# PIC32MK0512GPK100 register map
Vendor: Microchip
Registers are 32-bit, read-write, reset 0x0 unless marked. A register's access mark holds for its fields unless they carry their own. Addresses are absolute, and some are shared; only a register's first bit layout is shown; [hi:lo] are bit positions; {n}, {i} and the like mark numbered series; 'fields as' and 'values as' point back to an identical list.

## RTCC
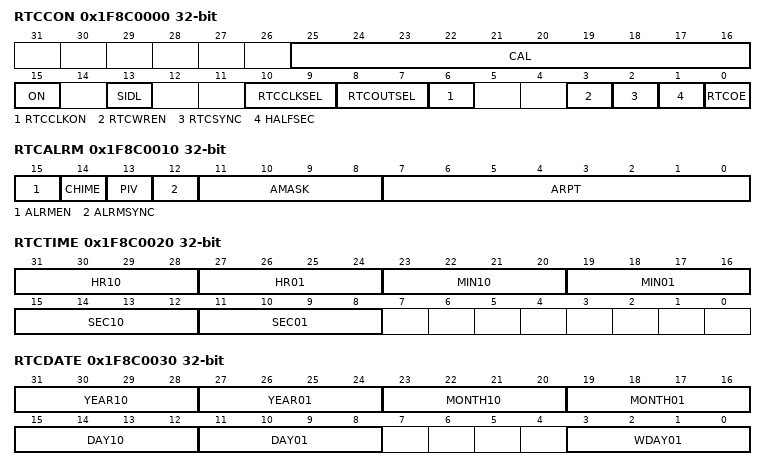
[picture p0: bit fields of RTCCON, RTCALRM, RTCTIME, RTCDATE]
0x1F8C0000 RTCCON
  [25:16] CAL, [15] ON, [13] SIDL, [10:9] RTCCLKSEL, [8:7] RTCOUTSEL, [6] RTCCLKON, [3] RTCWREN, [2] RTCSYNC ro, [1] HALFSEC ro, [0] RTCOE
0x1F8C0010 RTCALRM
  [15] ALRMEN, [14] CHIME, [13] PIV, [12] ALRMSYNC, [11:8] AMASK, [7:0] ARPT
0x1F8C0020 RTCTIME reset not defined — (power-on value 000xxxxxxxxxxxxx0xxxxxxx--------)
  [31:28] HR10, [27:24] HR01, [23:20] MIN10, [19:16] MIN01, [15:12] SEC10, [11:8] SEC01
0x1F8C0030 RTCDATE reset not defined — (power-on value xxxxxxxx000xxxxx00xxxxxx----0xxx)
  [31:28] YEAR10, [27:24] YEAR01, [23:20] MONTH10, [19:16] MONTH01, [15:12] DAY10, [11:8] DAY01, [3:0] WDAY01
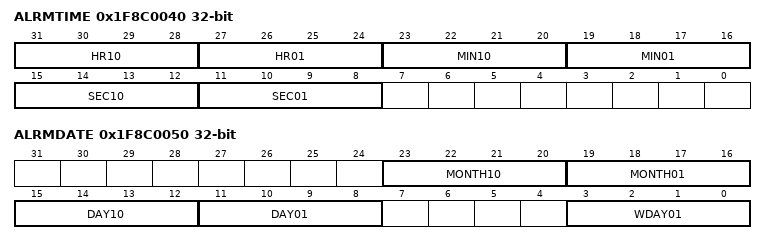
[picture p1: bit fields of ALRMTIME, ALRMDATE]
0x1F8C0040 ALRMTIME reset not defined — (power-on value 000xxxxx0xxxxxxx0xxxxxxx--------)
  fields as RTCTIME
0x1F8C0050 ALRMDATE reset not defined — (power-on value --------000xxxxx00xxxxxx----0xxx)
  [23:20] MONTH10, [19:16] MONTH01, [15:12] DAY10, [11:8] DAY01, [3:0] WDAY01

## lpwr_deep_sleep_ctrl
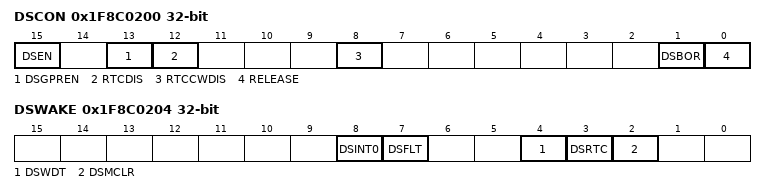
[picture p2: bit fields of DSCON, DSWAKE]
0x1F8C0200 DSCON
  [15] DSEN, [13] DSGPREN, [12] RTCDIS, [8] RTCCWDIS, [1] DSBOR, [0] RELEASE
0x1F8C0204 DSWAKE
  [8] DSINT0, [7] DSFLT, [4] DSWDT, [3] DSRTC, [2] DSMCLR
0x1F8C0208 DSGPR0
  [31:0] DSGPR
{0x1F8C020C+4i} DSGPR{i} (i=1..32)
  [31:0] DSGPR

## SB
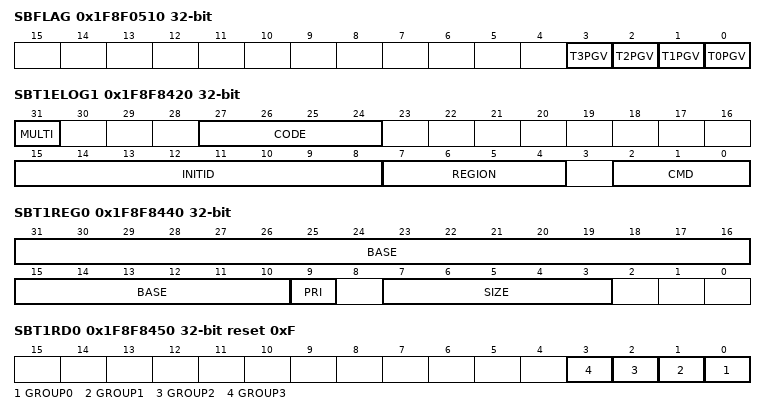
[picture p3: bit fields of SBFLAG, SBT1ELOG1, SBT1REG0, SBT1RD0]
0x1F8F0510 SBFLAG ro
  [n] T{n}PGV (n=0..3)
0x1F8F8420 SBT1ELOG1
  [31] MULTI, [27:24] CODE, [15:8] INITID ro, [7:4] REGION ro, [2:0] CMD ro
0x1F8F8424 SBT1ELOG2 ro
  [1:0] GROUP
0x1F8F8428 SBT1ECON
  [24] ERRP
0x1F8F8430 SBT1ECLRS ro
  [0] CLEAR
0x1F8F8438 SBT1ECLRM ro
  [0] CLEAR
0x1F8F8440 SBT1REG0 reset not defined — (power-on value 0000000000000000000000x-00000---)
  [31:10] BASE, [9] PRI ro, [7:3] SIZE
0x1F8F8450 SBT1RD0 reset 0xF
  [n] GROUP{n} (n=0..3)
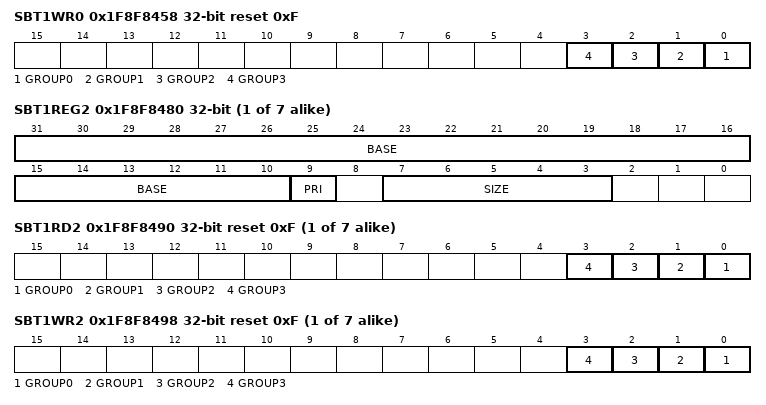
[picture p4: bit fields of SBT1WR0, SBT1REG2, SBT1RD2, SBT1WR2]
0x1F8F8458 SBT1WR0 reset 0xF
  [n] GROUP{n} (n=0..3)
{0x1F8F8440+0x20*i} SBT1REG{i} reset not defined (i=2..8) — (power-on value 0000000000000000000000x-00000---)
  [31:10] BASE, [9] PRI ro, [7:3] SIZE
{0x1F8F8450+0x20*i} SBT1RD{i} reset 0xF (i=2..8)
  [n] GROUP{n} (n=0..3)
{0x1F8F8458+0x20*i} SBT1WR{i} reset 0xF (i=2..8)
  [n] GROUP{n} (n=0..3)

## DOS_EIP_00136_ssx
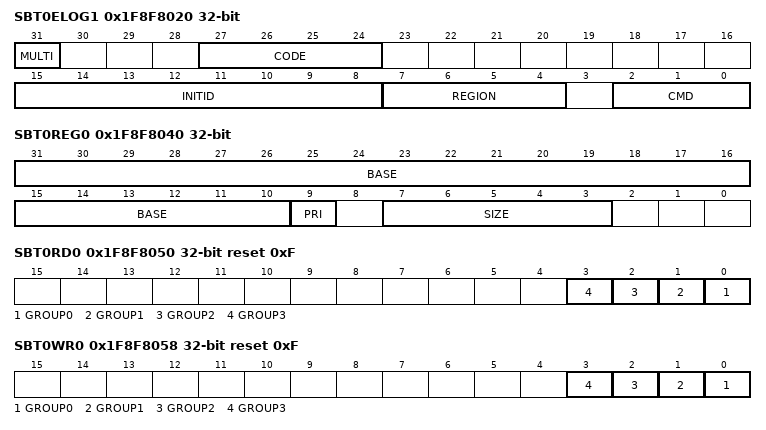
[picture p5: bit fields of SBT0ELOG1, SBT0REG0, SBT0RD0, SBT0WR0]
0x1F8F8020 SBT0ELOG1
  [31] MULTI, [27:24] CODE, [15:8] INITID ro, [7:4] REGION ro, [2:0] CMD ro
0x1F8F8024 SBT0ELOG2 ro
  [1:0] GROUP
0x1F8F8028 SBT0ECON
  [24] ERRP
0x1F8F8030 SBT0ECLRS ro
  [0] CLEAR
0x1F8F8038 SBT0ECLRM ro
  [0] CLEAR
0x1F8F8040 SBT0REG0 reset not defined — (power-on value 0000000000000000000000x-00000---)
  [31:10] BASE, [9] PRI ro, [7:3] SIZE
0x1F8F8050 SBT0RD0 reset 0xF
  [n] GROUP{n} (n=0..3)
0x1F8F8058 SBT0WR0 reset 0xF
  [n] GROUP{n} (n=0..3)
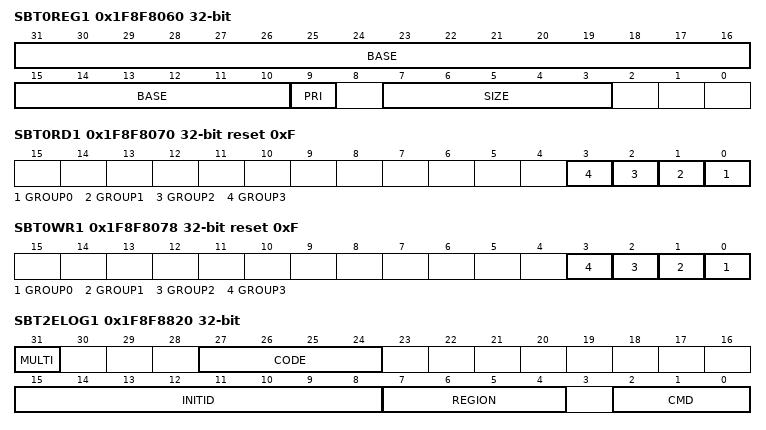
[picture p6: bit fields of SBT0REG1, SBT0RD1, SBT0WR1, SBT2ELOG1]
0x1F8F8060 SBT0REG1 reset not defined — (power-on value 0000000000000000000000x-00000---)
  [31:10] BASE, [9] PRI ro, [7:3] SIZE
0x1F8F8070 SBT0RD1 reset 0xF
  [n] GROUP{n} (n=0..3)
0x1F8F8078 SBT0WR1 reset 0xF
  [n] GROUP{n} (n=0..3)
0x1F8F8820 SBT2ELOG1
  fields as SBT0ELOG1
0x1F8F8824 SBT2ELOG2 ro
  [1:0] GROUP
0x1F8F8828 SBT2ECON
  [24] ERRP
0x1F8F8830 SBT2ECLRS ro
  [0] CLEAR
0x1F8F8838 SBT2ECLRM ro
  [0] CLEAR
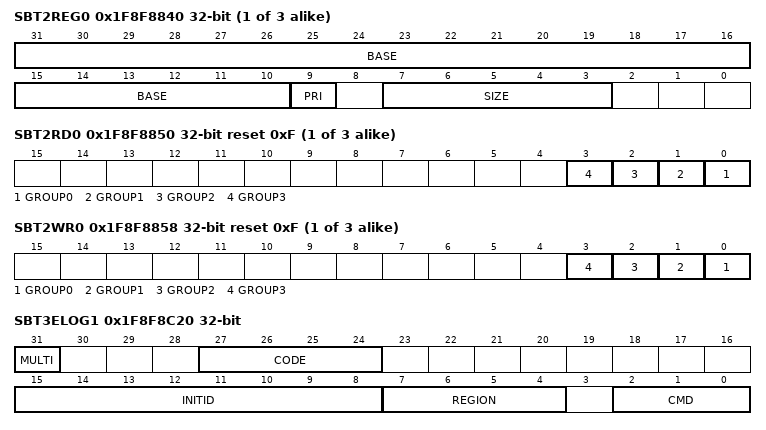
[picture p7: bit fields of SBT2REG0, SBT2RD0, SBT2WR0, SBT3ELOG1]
{0x1F8F8840+0x20*i} SBT2REG{i} reset not defined (i=0..2) — (power-on value 0000000000000000000000x-00000---)
  [31:10] BASE, [9] PRI ro, [7:3] SIZE
{0x1F8F8850+0x20*i} SBT2RD{i} reset 0xF (i=0..2)
  [n] GROUP{n} (n=0..3)
{0x1F8F8858+0x20*i} SBT2WR{i} reset 0xF (i=0..2)
  [n] GROUP{n} (n=0..3)
0x1F8F8C20 SBT3ELOG1
  fields as SBT0ELOG1
0x1F8F8C24 SBT3ELOG2 ro
  [1:0] GROUP
0x1F8F8C28 SBT3ECON
  [24] ERRP
0x1F8F8C30 SBT3ECLRS ro
  [0] CLEAR
0x1F8F8C38 SBT3ECLRM ro
  [0] CLEAR
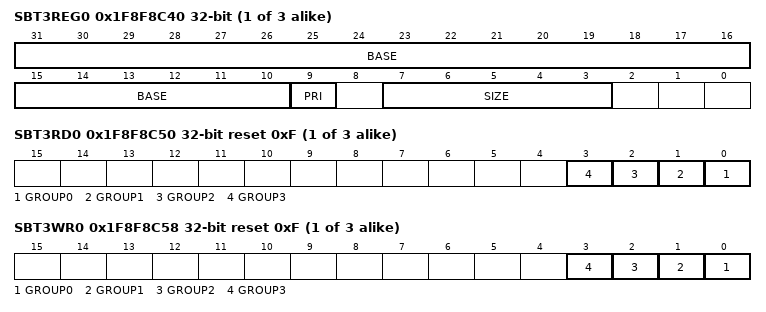
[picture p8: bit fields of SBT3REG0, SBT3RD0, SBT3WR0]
{0x1F8F8C40+0x20*i} SBT3REG{i} reset not defined (i=0..2) — (power-on value 0000000000000000000000x-00000---)
  [31:10] BASE, [9] PRI ro, [7:3] SIZE
{0x1F8F8C50+0x20*i} SBT3RD{i} reset 0xF (i=0..2)
  [n] GROUP{n} (n=0..3)
{0x1F8F8C58+0x20*i} SBT3WR{i} reset 0xF (i=0..2)
  [n] GROUP{n} (n=0..3)
